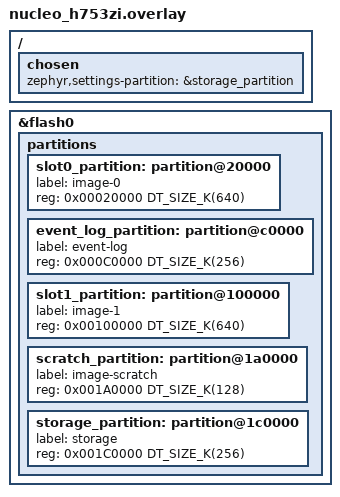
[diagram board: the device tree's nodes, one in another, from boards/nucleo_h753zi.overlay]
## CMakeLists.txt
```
cmake_minimum_required(VERSION 3.20.0)

# The following is optional and effectively ignored if a different board is chosen via a parameter.
# In general, it seems to be more appropriate to specify the board when invoking west or CMake
# directly, or, e.g., use `west config build.board nrf52840dk/nrf52840`.
#set(BOARD nucleo_h753zi)

# The following resolves the Zephyr location using the ZEPHYR_BASE environment variable.
# The `REQUIRED HINTS $ENV{ZEPHYR_BASE}` is optional in case you're not using `west zephyr-export`
# https://docs.zephyrproject.org/latest/develop/west/zephyr-cmds.html#installing-cmake-packages-west-zephyr-export
find_package(Zephyr REQUIRED HINTS $ENV{ZEPHYR_BASE})

project(
    example_1
    VERSION 0.1
    DESCRIPTION "A simple Zephyr application demonstrating a freestanding configuration."
    LANGUAGES C
)

target_include_directories(
        app
        PRIVATE
        include
)


# The target "app" is defined in Zephyr's CMake package and is the default target for Zephyr apps.
target_sources(
    app
    PRIVATE
    src/main.c
    src/blink_thread.c
    src/switch_thread.c
)
```

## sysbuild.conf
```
# Sysbuild configuration — co-builds MCUboot alongside the application.
# Used when building with: west build -b <board> --sysbuild
SB_CONFIG_BOOTLOADER_MCUBOOT=y
```

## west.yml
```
manifest:
  remotes:
    - name: zephyrproject-rtos
      url-base: https://github.com/zephyrproject-rtos

  projects:
    - name: zephyr
      remote: zephyrproject-rtos
      revision: main              # ← PINNED version! make sure your sdk version matches 
      import: true                   # ← This pulls in all Zephyr's module deps

  self:
    path: zephyr_freestanding
```

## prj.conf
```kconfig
# This project configuration is the default file expected by the build system.
# Unless a different file is specified using the `CONF_FILE` CMake variable, you'll need to
# provide this file even if it is empty.
#
# This template ships with optional features in src/ and include/ that are NOT
# compiled by default. To enable a feature you typically need three things:
#   1. Add the source file(s) to CMakeLists.txt
#   2. Uncomment the matching `# === <feature> ===` block below
#   3. (For event_log) ensure the board overlay defines event_log_partition
# See docs/feature_selection_guide.md for the per-feature recipe.

CONFIG_GPIO=y # Enable GPIO support, which is commonly used for controlling LEDs and reading button states.
CONFIG_PRINTK=y # Enable printk support for debugging output.

# === Logging ===
# CONFIG_LOG=y
# CONFIG_LOG_DEFAULT_LEVEL=3   # 0=off, 1=err, 2=warn, 3=info, 4=dbg

# === Persistent config (config_store: src/config_store.c) ==================
# Stores key-value settings on a dedicated flash partition (ZMS backend).
# Requires storage_partition in the board overlay (already defined in
# boards/nucleo_h753zi.overlay).
# CONFIG_FLASH=y
# CONFIG_FLASH_MAP=y
# CONFIG_FLASH_PAGE_LAYOUT=y
# CONFIG_ZMS=y
# CONFIG_SETTINGS=y
# CONFIG_SETTINGS_ZMS=y

# === Networking (W5500 + DHCP + sockets) ====================================
# Required by REST API, OTA, and any feature that talks over the network.
# CONFIG_NETWORKING=y
# CONFIG_NET_IPV4=y
# CONFIG_NET_TCP=y
# CONFIG_NET_UDP=y
# CONFIG_NET_SOCKETS=y
# CONFIG_NET_DHCPV4=y
# CONFIG_NET_L2_ETHERNET=y
# CONFIG_ETH_W5500=y
# CONFIG_SPI=y

# === HTTP server (REST API: src/rest_api.c) =================================
# Optional, requires Networking above.
# CONFIG_HTTP_SERVER=y
# CONFIG_HTTP_PARSER=y
# CONFIG_HTTP_PARSER_URL=y
# CONFIG_JSON_LIBRARY=y
# CONFIG_ZVFS=y
# CONFIG_ZVFS_EVENTFD=y
# CONFIG_ZVFS_EVENTFD_MAX=4   # bug_reports/016 — default of 1 is too small

# === MCUboot OTA + MCUmgr (UDP transport: src/ota.c) =======================
# Requires Networking above and a sysbuild build (`west build --sysbuild`).
# CONFIG_BOOTLOADER_MCUBOOT=y
# CONFIG_IMG_MANAGER=y
# CONFIG_STREAM_FLASH=y
# CONFIG_MCUMGR=y
# CONFIG_MCUMGR_TRANSPORT_UDP=y
# CONFIG_MCUMGR_GRP_IMG=y
# CONFIG_MCUMGR_GRP_OS=y

# === Event log (FCB ring: src/event_log.c) =================================
# Requires config_store, an event_log_partition in the board overlay
# (already defined in boards/nucleo_h753zi.overlay), and CONFIG_LOG above.
# CONFIG_FCB=y
# CONFIG_CRC=y

# === Time service (SNTP: src/time_service.c) ===============================
# Requires Networking and config_store above.
# CONFIG_SNTP=y
# CONFIG_POSIX_API=y
# CONFIG_POSIX_TIMERS=y
# CONFIG_DNS_RESOLVER=y
# CONFIG_DNS_SERVER_IP_ADDRESSES=y
# CONFIG_DNS_SERVER1="8.8.8.8"
```

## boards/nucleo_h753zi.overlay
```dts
/*
 * Application board overlay for nucleo_h753zi
 *
 * Replaces the default flash partition layout with an MCUboot-compatible
 * layout that includes:
 *   - a 256 KB storage partition for ZMS persistent settings, and
 *   - a 256 KB event-log partition (FCB ring buffer for event_log.c).
 *
 * Both sit outside the MCUboot swap area, so persistent state and event
 * history survive firmware updates.
 *
 * Flash layout (STM32H753 dual-bank, 2 MB total):
 *   0x08000000  boot_partition       128 KB  (MCUboot)
 *   0x08020000  slot0_partition      640 KB  (primary app image, bank 1)
 *   0x080C0000  event_log_partition  256 KB  (FCB ring, 2 x 128 KB sectors)
 *   0x08100000  slot1_partition      640 KB  (secondary image, bank 2 start)
 *   0x081A0000  scratch_partition    128 KB  (MCUboot swap scratch)
 *   0x081C0000  storage_partition    256 KB  (ZMS persistent settings)
 *                                    -------
 *                                    2048 KB total
 *
 * Slot1 deliberately starts at 0x100000 (bank 2) so MCUboot swaps stay
 * within a single bank's erase domain. The event-log partition fills the
 * tail of bank 1 between slot0 and the bank boundary.
 *
 * This overlay must match sysbuild/mcuboot/boards/nucleo_h753zi.overlay.
 */

/* Delete the base board's default partition nodes */
&flash0 {
    partitions {
        /delete-node/ partition@20000;  /* old slot0 */
        /delete-node/ partition@60000;  /* old slot1 */
        /delete-node/ partition@c0000;  /* old storage */

        /* Primary app image: 640 KB (5 x 128 KB sectors) */
        slot0_partition: partition@20000 {
            label = "image-0";
            reg = <0x00020000 DT_SIZE_K(640)>;
        };

        /* Event log FCB ring: 256 KB (2 x 128 KB sectors), tail of bank 1 */
        event_log_partition: partition@c0000 {
            label = "event-log";
            reg = <0x000C0000 DT_SIZE_K(256)>;
        };

        /* Secondary / upgrade image: 640 KB (bank 2 start) */
        slot1_partition: partition@100000 {
            label = "image-1";
            reg = <0x00100000 DT_SIZE_K(640)>;
        };

        /* MCUboot swap scratch: 128 KB */
        scratch_partition: partition@1a0000 {
            label = "image-scratch";
            reg = <0x001A0000 DT_SIZE_K(128)>;
        };

        /* ZMS persistent settings: 256 KB (outside MCUboot swap area) */
        storage_partition: partition@1c0000 {
            label = "storage";
            reg = <0x001C0000 DT_SIZE_K(256)>;
        };
    };
};

/* Point the settings subsystem at the storage partition */
/ {
    chosen {
        zephyr,settings-partition = &storage_partition;
    };
};
```

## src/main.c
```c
#include <zephyr/kernel.h>
#include "blink_thread.h"
#include "switch_thread.h"
#include "state_machines.h"

/*
 * ============================================================================
 * Optional module headers
 * ----------------------------------------------------------------------------
 * Uncomment the includes for the modules you enable in CMakeLists.txt and
 * prj.conf.  See docs/feature_selection_guide.md for the per-feature recipe.
 * ============================================================================
 */
/* #include "config_store.h" */
/* #include "w5500_net.h" */
/* #include "command_uart.h" */
/* #include "rest_api.h" */
/* #include "ota.h" */
/* #include "event_log.h" */
/* #include "time_service.h" */

/* mutex to protect access to shared state variables 
similar to python's threading.Lock, this ensures that only one thread can access the shared state variables at a time
*/
K_MUTEX_DEFINE(blink_led_mutex);  
K_MUTEX_DEFINE(blink_enabled_mutex);  

/* shared state variables */
volatile bool blink_enabled = true;
volatile struct gpio_dt_spec blinking_led;

int main(void)
{
    printk("Starting Zephyr Blinky with Threads Example\n");
    printk("blinking thread priority: %d, button thread priority: %d\n", BLINK_PRIORITY, BTN_PRIORITY);

    /* Initialize the blinking LED to led0 by default */
    blinking_led = led0;

    /* Create the blink thread */
    k_thread_create(&blink_thread_data, blink_stack, BLINK_STACK_SIZE,
                    blink_thread_entry, NULL, NULL, NULL,
                    BLINK_PRIORITY, 0, K_NO_WAIT);

    /* Create the button thread */
    k_thread_create(&btn_thread_data, btn_stack, BTN_STACK_SIZE,
                    btn_thread_entry, NULL, NULL, NULL,
                    BTN_PRIORITY, 0, K_NO_WAIT);

    /*
     * ========================================================================
     * Optional module thread spawns
     * ------------------------------------------------------------------------
     * Each block below corresponds to an optional feature module shipped in
     * src/ but NOT compiled by default.  Add the source file to
     * CMakeLists.txt, uncomment the matching block in prj.conf, and
     * uncomment the spawn here.  See docs/feature_selection_guide.md.
     *
     * Recommended spawn order (dependencies first):
     *   config_store -> w5500_net -> time_service -> event_log -> command_uart
     *   -> rest_api -> ota
     * ========================================================================
     */

    /* k_thread_create(&config_store_thread_data, config_store_stack,
     *                 CONFIG_STORE_STACK_SIZE, config_store_thread_entry,
     *                 NULL, NULL, NULL, CONFIG_STORE_PRIORITY, 0, K_NO_WAIT); */

    /* k_thread_create(&net_thread_data, net_stack, NET_STACK_SIZE,
     *                 net_thread_entry, NULL, NULL, NULL,
     *                 NET_PRIORITY, 0, K_NO_WAIT); */

    /* k_thread_create(&time_service_thread_data, time_service_stack,
     *                 TIME_SERVICE_STACK_SIZE, time_service_thread_entry,
     *                 NULL, NULL, NULL, TIME_SERVICE_PRIORITY, 0, K_NO_WAIT); */

    /* k_thread_create(&event_log_thread_data, event_log_stack,
     *                 EVENT_LOG_STACK_SIZE, event_log_thread_entry,
     *                 NULL, NULL, NULL, EVENT_LOG_PRIORITY, 0, K_NO_WAIT); */

    /* k_thread_create(&command_uart_thread_data, command_uart_stack,
     *                 COMMAND_UART_STACK_SIZE, command_uart_thread_entry,
     *                 NULL, NULL, NULL, COMMAND_UART_PRIORITY, 0, K_NO_WAIT); */

    /* k_thread_create(&rest_api_thread_data, rest_api_stack,
     *                 REST_API_STACK_SIZE, rest_api_thread_entry,
     *                 NULL, NULL, NULL, REST_API_PRIORITY, 0, K_NO_WAIT); */

    /* k_thread_create(&ota_thread_data, ota_stack, OTA_STACK_SIZE,
     *                 ota_thread_entry, NULL, NULL, NULL,
     *                 OTA_PRIORITY, 0, K_NO_WAIT); */

    printk("System started: 3 threads (main + button + blink)\n");

    while (1) {
        /* Main thread can perform other tasks or just sleep */
        k_sleep(K_FOREVER);
    }
    return 0;
}
```

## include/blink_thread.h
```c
#ifndef BLINK_THREAD_H
#define BLINK_THREAD_H

#define BLINK_STACK_SIZE 1024
#define BLINK_PRIORITY   3     /* Lower priority than button */

#include <stdbool.h>
#include <zephyr/kernel.h>
#include <zephyr/drivers/gpio.h>

#define LED0_NODE DT_ALIAS(led0)
#define LED1_NODE DT_ALIAS(led1)
extern const struct gpio_dt_spec led0;
extern const struct gpio_dt_spec led1;

extern struct k_thread blink_thread_data;
extern k_thread_stack_t blink_stack[];

/* entry point for the blink thread, this is where the blinking logic will be implemented */
void blink_thread_entry(void *p1, void *p2, void *p3); 
#endif /* BLINK_THREAD_H */
```

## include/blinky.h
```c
#ifndef BLINKY_H
#define BLINKY_H

#include <zephyr/drivers/gpio.h>

#define LED0_NODE DT_ALIAS(led0)
#define LED1_NODE DT_ALIAS(led1)
extern const struct gpio_dt_spec led0;
extern const struct gpio_dt_spec led1;
int blinky(void);
int led_init(void);


#endif /* BLINKY_H */
```

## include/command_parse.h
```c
#ifndef COMMAND_PARSE_H
#define COMMAND_PARSE_H

/**
 * @file command_parse.h
 * @brief Pure command-string parser for the UART interface.
 *
 * Converts a raw command string into a structured result (command ID
 * plus arguments) without performing any side effects.  This module
 * has no Zephyr dependencies and can be unit-tested on native_sim.
 */

#include <stddef.h>

/** Maximum length of a single argument extracted from a command. */
#define CMD_ARG_MAX_LEN 48

/** Recognised command identifiers. */
enum cmd_id {
    CMD_HELP,
    CMD_PING,
    CMD_IP_GET,
    CMD_IP_SET,
    CMD_IP_SET_DHCP,
    CMD_CONFIG_DUMP,
    CMD_CONFIG_FACTORY_RESET,
    CMD_EVENT_LOG,
    CMD_LOG_LEVEL_SET,
    CMD_LOG_DROP,
    CMD_TIME_GET,
    CMD_TIME_SET,
    CMD_TIME_SYNC,
    CMD_UNKNOWN,
};

/**
 * @brief Result of parsing a command string.
 *
 * `id` identifies the command.  For commands that accept positional
 * arguments (currently only `ip_set`) the first three space-separated
 * tokens after the keyword are stored in arg1 / arg2 / arg3.
 * Unused argument slots are zero-filled (empty strings).
 */
struct parsed_command {
    enum cmd_id id;
    char arg1[CMD_ARG_MAX_LEN];
    char arg2[CMD_ARG_MAX_LEN];
    char arg3[CMD_ARG_MAX_LEN];
};

/**
 * @brief Parse a null-terminated UART command string into a structured result.
 *
 * Leading whitespace is stripped.  The first token is matched against
 * known keywords (case-sensitive).  For `ip_set`, the three tokens
 * following the keyword are extracted into @p out->arg1 / arg2 / arg3.
 * If the input is empty after trimming, the command is reported as
 * CMD_UNKNOWN.  The function itself never fails on malformed input —
 * unrecognised strings yield CMD_UNKNOWN with return code 0.
 *
 * @param input Null-terminated command string received from UART.
 *              May be NULL (returns -1).
 * @param out   Output structure populated on return.
 *              May be NULL (returns -1).
 * @return 0 on success (including CMD_UNKNOWN), -1 only if a pointer is NULL.
 */
int parse_command(const char *input, struct parsed_command *out);

#endif /* COMMAND_PARSE_H */
```

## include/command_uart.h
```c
#ifndef COMMAND_UART_H
#define COMMAND_UART_H

/**
 * @file command_uart.h
 * @brief UART command interface module.
 *
 * Provides an interrupt-driven UART RX command interface
 * on the console UART. Supports a simple command dispatcher
 * that can be extended with application-specific commands.
 */

#include <zephyr/kernel.h>

/* ---------- Thread configuration ---------- */
#define UART_STACK_SIZE 1024
#define UART_PRIORITY   4

/* ---------- Thread resources (defined in uart.c) ---------- */
extern struct k_thread uart_thread_data;
extern k_thread_stack_t uart_stack[];

/* ---------- Module API ---------- */

/**
 * @brief UART module thread entry point.
 *
 * Initializes interrupt-driven UART RX, then loops waiting
 * for complete command lines and dispatching them.
 * Created by main() via k_thread_create().
 *
 * @param p1 Unused.
 * @param p2 Unused.
 * @param p3 Unused.
 */
void command_uart_thread_entry(void *p1, void *p2, void *p3);

#endif /* COMMAND_UART_H */
```

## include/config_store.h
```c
#ifndef CONFIG_STORE_H
#define CONFIG_STORE_H

/**
 * @file config_store.h
 * @brief Persistent configuration store using Zephyr's settings subsystem.
 *
 * Provides persistent key-value storage backed by ZMS flash. All configs
 * survive reboots and firmware updates (the storage partition is outside
 * the MCUboot slot0/slot1 swap area).
 *
 * Architecture:
 *   - Each config group (e.g. "heartbeat", "system") is a settings subtree.
 *   - The init thread calls settings_subsys_init -> settings_load -> dump.
 *   - Setters persist immediately via settings_save_one().
 *   - Thread-safe: a mutex protects all config variables.
 *
 * Adding a new config:
 *   1. Add a variable with a default in config_store.c
 *   2. Add a case in the h_set callback (for load from flash)
 *   3. Add an export line in h_export (for save-all)
 *   4. Add getter/setter functions
 *   5. Add a line to config_store_dump()
 */

#include <zephyr/kernel.h>
#include <stdbool.h>
#include <stdint.h>

/* ---------- Thread configuration ---------- */
#define CONFIG_STORE_STACK_SIZE  4096
#define CONFIG_STORE_PRIORITY    6

/* ---------- String length limits ---------- */
#define CONFIG_STORE_URL_MAX_LEN         256
#define CONFIG_STORE_NAME_MAX_LEN        64
#define CONFIG_STORE_NTP_SERVER_MAX_LEN  64
#define CONFIG_STORE_IP_ADDR_MAX_LEN    16  /* "255.255.255.255\0" */

/* ---------- Log verbosity (used by event_log) ---------- */

/**
 * @brief Log verbosity levels persisted under "event_log/logVerbosity".
 *
 * Maps to event_log severity filter:
 *   ERROR → drops WARN/NOTICE/INFO/DEBUG
 *   WARN  → drops NOTICE/INFO/DEBUG
 *   INFO  → drops only DEBUG
 *   DEBUG → logs everything
 */
enum mcu_log_verbosity {
    MCU_LOG_ERROR = 0,
    MCU_LOG_WARN  = 1,
    MCU_LOG_INFO  = 2,
    MCU_LOG_DEBUG = 3,
};

/* ---------- Thread resources (defined in config_store.c) ---------- */
extern struct k_thread config_store_thread_data;
extern k_thread_stack_t config_store_stack[];

void config_store_thread_entry(void *p1, void *p2, void *p3);
void config_store_dump(void);

/* ---------- heartbeat/ getters & setters ---------- */

bool config_store_get_heartbeat_enabled(void);
int config_store_set_heartbeat_enabled(bool enabled);
int config_store_get_heartbeat_url(char *buf, size_t buf_len);
int config_store_set_heartbeat_url(const char *url);
uint32_t config_store_get_heartbeat_interval(void);
int config_store_set_heartbeat_interval(uint32_t interval_s);

/* ---------- system/ getters & setters ---------- */

int config_store_get_system_name(char *buf, size_t buf_len);
int config_store_set_system_name(const char *name);

/* ---------- event_log/ getters & setters ---------- */

enum mcu_log_verbosity config_store_get_log_verbosity(void);
int config_store_set_log_verbosity(enum mcu_log_verbosity v);
uint32_t config_store_get_boot_count(void);
int config_store_set_boot_count(uint32_t count);

/* ---------- time_service/ getters & setters ---------- */

int config_store_get_ntp_server(char *buf, size_t buf_len);
int config_store_set_ntp_server(const char *server);
uint32_t config_store_get_ntp_sync_interval(void);
int config_store_set_ntp_sync_interval(uint32_t seconds);

/* ---------- network/ getters & setters ---------- */

int config_store_get_ip_address(char *buf, size_t buf_len);
int config_store_set_ip_address(const char *addr);
int config_store_get_ip_mask(char *buf, size_t buf_len);
int config_store_set_ip_mask(const char *mask);
int config_store_get_ip_gateway(char *buf, size_t buf_len);
int config_store_set_ip_gateway(const char *gw);

/* ---------- Factory reset ---------- */

int config_store_factory_reset(void);

#endif /* CONFIG_STORE_H */
```

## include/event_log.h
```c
#ifndef EVENT_LOG_H
#define EVENT_LOG_H

/**
 * @file event_log.h
 * @brief Flash-backed circular event log using Zephyr FCB.
 *
 * Provides a ring-buffer event log stored on a dedicated flash partition
 * ("event-log", 256 KB / 2 sectors).  Events are 76-byte fixed-size
 * records with a severity level modelled after Linux syslog (RFC 5424).
 *
 * The runtime filter level is driven by config_store's mcu_log_verbosity:
 *   MCU_LOG_ERROR → EVENT_SEV_ERR   (drops WARN/NOTICE/INFO/DEBUG)
 *   MCU_LOG_WARN  → EVENT_SEV_WARN  (drops NOTICE/INFO/DEBUG)
 *   MCU_LOG_INFO  → EVENT_SEV_INFO  (drops only DEBUG)
 *   MCU_LOG_DEBUG → EVENT_SEV_DEBUG (logs everything)
 *
 * Thread-safe — all public functions may be called from any context.
 *
 * To add a new event type:
 *   1. Add an entry to enum event_type (before EVENT_TYPE_COUNT).
 *   2. Add a string in event_type_to_str() in event_log.c.
 *   That's it — no registration required.
 */

#include <zephyr/kernel.h>
#include <stdint.h>
#include <stdbool.h>

/* ---------- Thread configuration ---------- */
#define EVENT_LOG_STACK_SIZE   2048
#define EVENT_LOG_PRIORITY     7
#define EVENT_LOG_MSG_MAX_LEN  64

/* ---------- Severity levels (RFC 5424 / Linux syslog) ---------- */

/**
 * @brief Event severity levels, modelled after Linux kernel log levels.
 *
 * Lower numeric value = higher severity.  The runtime filter drops
 * events whose severity value is strictly greater than the current level.
 *
 * @par Level table
 * | Value | Name   | Description                        |
 * |-------|--------|------------------------------------|
 * | 0     | EMERG  | System is unusable                 |
 * | 1     | ALERT  | Action must be taken immediately   |
 * | 2     | CRIT   | Critical conditions                |
 * | 3     | ERR    | Error conditions                   |
 * | 4     | WARN   | Warning conditions                 |
 * | 5     | NOTICE | Normal but significant             |
 * | 6     | INFO   | Informational messages             |
 * | 7     | DEBUG  | Debug-level messages               |
 */
enum event_severity {
    EVENT_SEV_EMERG  = 0,
    EVENT_SEV_ALERT  = 1,
    EVENT_SEV_CRIT   = 2,
    EVENT_SEV_ERR    = 3,
    EVENT_SEV_WARN   = 4,
    EVENT_SEV_NOTICE = 5,
    EVENT_SEV_INFO   = 6,
    EVENT_SEV_DEBUG  = 7,
};

/* ---------- Event types ---------- */

/**
 * @brief Categories of events recorded in the log.
 *
 * @par Type table
 * | Value | Name    | Typical use                        |
 * |-------|---------|------------------------------------|
 * | 0     | BOOT    | System boot / reboot               |
 * | 1     | NETWORK | DHCP, link up/down, IP changes     |
 * | 2     | OTA     | Image confirmed, upgrade started   |
 * | 3     | CONFIG  | Config store changes via REST API   |
 * | 4     | WEBHOOK | Keepalive / notification POST       |
 * | 5     | SYSTEM  | Module init, general system events  |
 * | 6     | USER    | User-triggered actions              |
 */
enum event_type {
    EVENT_TYPE_BOOT = 0,
    EVENT_TYPE_NETWORK,
    EVENT_TYPE_OTA,
    EVENT_TYPE_CONFIG,
    EVENT_TYPE_WEBHOOK,
    EVENT_TYPE_SYSTEM,
    EVENT_TYPE_USER,
    EVENT_TYPE_COUNT,
};

/* ---------- Event entry structure ---------- */

/**
 * @brief A single event log entry (80 bytes, packed).
 *
 * Stored directly in flash via FCB.
 *
 * Three independent timestamps tag each record:
 *   - `timestamp`  — uptime seconds (`k_uptime_get()/1000`). Resets on
 *                    every reboot, unique within a boot.
 *   - `wall_clock` — UNIX epoch seconds if the time service was
 *                    synced at write time, 0 otherwise. Monotonic
 *                    across reboots (once synced), but 0 for every
 *                    pre-sync entry.
 *   - `boot_id`    — persistent, monotonically-increasing boot
 *                    counter (`mcu/bootCount`). Stamps every record
 *                    with the boot session it was written in, so
 *                    cross-boot noise can be filtered out even when
 *                    `wall_clock` is 0 (see bug report #019).
 *
 * @par Memory layout
 * @code
 * Offset  Size  Field
 * 0       4     timestamp   (uint32_t — uptime seconds)
 * 4       4     wall_clock  (uint32_t — UNIX epoch seconds, 0 if unsynced)
 * 8       4     boot_id     (uint32_t — persistent boot counter)
 * 12      1     event_type  (uint8_t  — enum event_type)
 * 13      1     severity    (uint8_t  — enum event_severity)
 * 14      2     data_len    (uint16_t — actual message length)
 * 16      64    message     (char[]   — NUL-padded description)
 * Total: 80 bytes
 * @endcode
 */
typedef struct {
    uint32_t timestamp;
    uint32_t wall_clock;
    uint32_t boot_id;
    uint8_t  event_type;
    uint8_t  severity;
    uint16_t data_len;
    char     message[EVENT_LOG_MSG_MAX_LEN];
} __packed event_entry_t;

/* ---------- Walk callback ---------- */

/**
 * @brief Callback invoked for each event during event_log_read().
 *
 * @param entry     Pointer to the deserialized event entry.
 * @param user_data Opaque context pointer passed through from the caller.
 * @return true to continue walking, false to stop early.
 *
 * @par Example
 * @code
 * static bool print_event(const event_entry_t *e, void *ctx) {
 *     printk("[%u] %s\n", e->timestamp, e->message);
 *     return true;  // continue
 * }
 * int count = event_log_read(0, print_event, NULL);
 * @endcode
 */
typedef bool (*event_log_walk_cb)(const event_entry_t *entry, void *user_data);

/* ---------- Thread resources (defined in event_log.c) ---------- */
extern struct k_thread event_log_thread_data;
extern k_thread_stack_t event_log_stack[];

/* ---------- Public API ---------- */

/**
 * @brief Initialize the FCB event log subsystem.
 *
 * Opens the "event-log" flash partition, queries sector geometry,
 * and calls fcb_init().  Called automatically by the event_log thread,
 * but exposed for unit tests that don't spawn the thread.
 *
 * @return 0 on success, negative errno on failure.
 *
 * @par Example
 * @code
 * int rc = event_log_init();
 * // rc == 0  → FCB ready
 * // rc == -ENODEV → flash partition not found
 * @endcode
 */
int event_log_init(void);

/**
 * @brief Write an event to the log.
 *
 * If the event's severity value is greater than the current filter
 * level, the event is silently dropped (returns 0).  Messages longer
 * than EVENT_LOG_MSG_MAX_LEN (64) bytes are truncated.
 *
 * @param sev  Severity level (EVENT_SEV_EMERG … EVENT_SEV_DEBUG).
 * @param type Event category (EVENT_TYPE_BOOT … EVENT_TYPE_USER).
 * @param msg  Human-readable description (NUL-terminated, max 64 chars).
 * @return 0 on success (including filtered-out events), negative errno on
 *         flash write failure.
 *
 * @par Examples
 * | sev          | type              | msg                  | filter=INFO | Result     |
 * |--------------|-------------------|----------------------|-------------|------------|
 * | EVENT_SEV_INFO  | EVENT_TYPE_BOOT | "system boot"     | INFO        | Written    |
 * | EVENT_SEV_DEBUG | EVENT_TYPE_SYSTEM | "heartbeat tick" | INFO        | Dropped    |
 * | EVENT_SEV_ERR   | EVENT_TYPE_OTA  | "confirm failed"  | INFO        | Written    |
 *
 * @code
 * event_log_write(EVENT_SEV_INFO, EVENT_TYPE_BOOT, "system boot");
 * event_log_write(EVENT_SEV_WARN, EVENT_TYPE_NETWORK, "link down");
 * @endcode
 */
int event_log_write(enum event_severity sev, enum event_type type,
                    const char *msg);

/**
 * @brief Read events from the log, filtered by time and/or boot ID.
 *
 * Walks the FCB from oldest to newest and invokes @p cb for each
 * entry that passes all active filters.  If the callback returns
 * false, the walk stops early.
 *
 * The filter is asymmetric by design, because a `boot_id` is only
 * needed to disambiguate entries whose `wall_clock` is 0 (pre-sync
 * entries — where per-boot uptime aliases across reboots). Entries
 * written after SNTP sync already carry a monotonic, cross-reboot
 * `wall_clock`, so they are filtered purely by @p since_wall and
 * are emitted regardless of the boot they came from.
 *
 * Default (@p boot_id_strict == false):
 *   1. `entry.wall_clock != 0` — sync'd entries: pass if
 *      `since_wall == 0 || entry.wall_clock >= since_wall`,
 *      regardless of boot.
 *   2. `entry.wall_clock == 0` — pre-sync entries: emitted iff
 *      the entry's boot is "in scope" for the requested window:
 *        - the entry's boot_id equals @p boot_id (current boot's
 *          pre-sync is always shown), OR
 *        - the entry's boot_id is strictly greater than the
 *          smallest boot_id whose sync'd entries fell inside the
 *          wall window (`min_in_window`). Younger boots that
 *          started inside the window contribute their pre-sync
 *          banner / DHCP / SNTP-failed diagnostics; the boot
 *          that produced `min_in_window` itself is excluded
 *          because its pre-sync occurred *before* the window.
 *      Pre-sync entries also honour @p since_uptime when set.
 *      When the log contains no sync'd entry inside the window
 *      (no anchor), pre-sync emission collapses to "current boot
 *      only" (same as the iteration-4 rule).
 *
 * Strict (@p boot_id_strict == true):
 *   - Every entry (sync'd or not) must also have
 *     `entry.boot_id == boot_id`. Used by `event_log_boot <id>`
 *     to replay one specific boot's full log.
 *
 * @param since_wall       Wall-clock cutoff (UNIX epoch). 0 = no
 *                         wall filter.
 * @param since_uptime     Uptime cutoff (s) for pre-sync entries.
 *                         0 = no uptime filter.
 * @param boot_id          Boot ID (0 = no boot filter).
 * @param boot_id_strict   If true, @p boot_id applies to every
 *                         entry. If false, only to pre-sync entries.
 * @param cb               Callback invoked per matching entry.
 * @param user_data        Opaque pointer forwarded to @p cb.
 * @return Number of entries passed to the callback (>= 0), or
 *         negative errno on FCB read failure.
 *
 * @par Example
 * @code
 * uint32_t bid = event_log_get_boot_id();
 *
 * // "Last 300 s of wall time, plus current boot's pre-sync".
 * // Sync'd entries from previous boots that fall in the window
 * // are included (their wall clocks are authoritative).
 * event_log_read(now_wall - 300, 0, bid, false, cb, ud);
 *
 * // Full replay of boot 42 (strict).
 * event_log_read(0, 0, 42, true,  cb, ud);
 *
 * // Every entry ever written.
 * event_log_read(0, 0, 0, false, cb, ud);
 * @endcode
 */
int event_log_read(uint32_t since_wall, uint32_t since_uptime,
                   uint32_t boot_id, bool boot_id_strict,
                   event_log_walk_cb cb, void *user_data);

/**
 * @brief Return the boot ID stamped on every entry written during
 *        this boot session.
 *
 * The value is loaded and incremented once by `event_log_init()`
 * from the persistent counter `mcu/bootCount` in config_store.
 * It is stable for the lifetime of the firmware's run.
 *
 * @return Current boot ID (>= 1 after a successful init; 0 if
 *         `event_log_init()` has not yet completed).
 *
 * @par Example
 * @code
 * uint32_t id = event_log_get_boot_id();
 * printk("this boot has id %u\n", id);
 * @endcode
 */
uint32_t event_log_get_boot_id(void);

/**
 * @brief Erase all events from the log.
 *
 * Performs a full FCB clear (erases all sectors except scratch).
 *
 * @return 0 on success, negative errno on flash erase failure.
 *
 * @par Example
 * @code
 * event_log_clear();
 * int n = event_log_read(0, my_cb, NULL);
 * // n == 0
 * @endcode
 */
int event_log_clear(void);

/**
 * @brief Erase all events from the log (alias for event_log_clear).
 *
 * Provided for API clarity; identical to event_log_clear().
 */
static inline int event_log_drop_all(void) { return event_log_clear(); }

/**
 * @brief Set the runtime severity filter level.
 *
 * Events with severity > level are silently dropped by event_log_write().
 * Thread-safe (uses atomic store).
 *
 * @param level Maximum severity value to accept (EVENT_SEV_EMERG … EVENT_SEV_DEBUG).
 *
 * @par Example
 * @code
 * event_log_set_level(EVENT_SEV_WARN);
 * // Now only EMERG, ALERT, CRIT, ERR, WARN are logged
 *
 * event_log_set_level(EVENT_SEV_DEBUG);
 * // Everything is logged
 * @endcode
 */
void event_log_set_level(enum event_severity level);

/**
 * @brief Get the current runtime severity filter level.
 *
 * @return Current filter level (EVENT_SEV_EMERG … EVENT_SEV_DEBUG).
 *
 * @par Example
 * @code
 * enum event_severity lvl = event_log_get_level();
 * // lvl == EVENT_SEV_INFO (default after init with MCU_LOG_INFO)
 * @endcode
 */
enum event_severity event_log_get_level(void);

/**
 * @brief Convert a severity enum to a human-readable string.
 *
 * @param sev Severity value.
 * @return Static string pointer (e.g. "INFO", "ERR", "DEBUG").
 *
 * @par Examples
 * | Input            | Output   |
 * |------------------|----------|
 * | EVENT_SEV_EMERG  | "EMERG"  |
 * | EVENT_SEV_ERR    | "ERR"    |
 * | EVENT_SEV_INFO   | "INFO"   |
 * | EVENT_SEV_DEBUG  | "DEBUG"  |
 */
const char *severity_to_str(enum event_severity sev);

/**
 * @brief Convert an event type enum to a human-readable string.
 *
 * @param type Event type value.
 * @return Static string pointer (e.g. "BOOT", "NETWORK", "CONFIG").
 *
 * @par Examples
 * | Input               | Output    |
 * |---------------------|-----------|
 * | EVENT_TYPE_BOOT     | "BOOT"    |
 * | EVENT_TYPE_NETWORK  | "NETWORK" |
 * | EVENT_TYPE_CONFIG   | "CONFIG"  |
 */
const char *event_type_to_str(enum event_type type);

/**
 * @brief Event log thread entry point.
 *
 * Sequence:
 *   1. Call event_log_init() to mount the FCB partition.
 *   2. Read mcu_log_verbosity from config_store → set filter level.
 *   3. Log the current filter level to the serial debug output.
 *   4. Report ready to the OTA health check.
 *   5. Write a boot event: "system boot".
 *   6. Sleep forever — events are written from other threads.
 *
 * @param p1 Unused.
 * @param p2 Unused.
 * @param p3 Unused.
 */
void event_log_thread_entry(void *p1, void *p2, void *p3);

#endif /* EVENT_LOG_H */
```

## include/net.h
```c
#ifndef NET_H
#define NET_H

/**
 * @file net.h
 * @brief W5500 network module interface.
 *
 * Provides network initialization, static IP configuration,
 * and DHCPv4 management for the W5500 Ethernet controller.
 */

#include <zephyr/kernel.h>
#include <zephyr/net/net_ip.h>

/* ---------- Thread configuration ---------- */
#define NET_STACK_SIZE 2048
#define NET_PRIORITY   5

/* ---------- IPv4 configuration ---------- */
struct net_ipv4_config {
    struct in_addr addr;
    struct in_addr netmask;
    struct in_addr gw;
};

/* ---------- Thread resources (defined in net.c) ---------- */
extern struct k_thread net_thread_data;
extern k_thread_stack_t net_stack[];

/* ---------- Module API ---------- */

/**
 * @brief Net module thread entry point.
 *
 * Initializes the W5500 interface, registers DHCP callback,
 * and starts the DHCP client. Created by main() via k_thread_create().
 *
 * @param p1 Unused.
 * @param p2 Unused.
 * @param p3 Unused.
 */
void net_thread_entry(void *p1, void *p2, void *p3);

/**
 * Set the IPv4 address, netmask, and gateway on the default network interface.
 * Stops DHCP if running before applying static config.
 * Returns 0 on success, negative errno on failure.
 */
int net_set_ip(const struct net_ipv4_config *cfg);

/**
 * Start DHCPv4 on the default network interface.
 * Removes any existing static IPv4 addresses first.
 * Returns 0 on success, negative errno on failure.
 */
int net_set_dhcp(void);

/**
 * Get the current IPv4 configuration (address, netmask, gateway).
 * Works for both static and DHCP-assigned addresses.
 * Returns 0 on success, -ENODEV if no interface, -ENOENT if no address.
 */
int net_get_ip(struct net_ipv4_config *cfg);

#endif /* NET_H */
```

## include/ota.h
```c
#ifndef OTA_H
#define OTA_H

/**
 * @file ota.h
 * @brief OTA firmware update module interface.
 *
 * Provides MCUmgr-based OTA updates over UDP with a health-based
 * image confirmation system. Each application module reports its
 * readiness after successful initialization. The OTA thread waits
 * for all modules to report ready before confirming the running
 * image with MCUboot, preventing auto-revert of a known-good firmware.
 *
 * To add a new module to the health check:
 *   1. Add an entry to the ota_module enum (before OTA_MODULE_COUNT).
 *   2. Call ota_report_module_ready() from the module after init succeeds.
 *   That's it — the OTA thread automatically checks all registered modules.
 */

#include <zephyr/kernel.h>

/* ---------- Thread configuration ---------- */
#define OTA_STACK_SIZE         2048
#define OTA_PRIORITY           8
#define OTA_CONFIRM_TIMEOUT_S  30

/* ---------- Module health registry ---------- */

/**
 * @brief Enumeration of all application modules tracked by the OTA health system.
 *
 * Each module that must be healthy before an OTA image is confirmed
 * gets an entry here. OTA_MODULE_COUNT is always last and serves as
 * the total module count for the bitmask.
 *
 * Customize this enum for your application — add/remove entries as needed.
 * Max 32 modules (limited by atomic_t width).
 */
enum ota_module {
    OTA_MODULE_NET,          /**< Network — ready after interface up and DHCP started */
    OTA_MODULE_UART,         /**< Command UART — ready after IRQ enabled */
    OTA_MODULE_REST_API,     /**< REST API — ready after HTTP server started */
    OTA_MODULE_CONFIG_STORE, /**< Config store — ready after settings loaded */
    OTA_MODULE_EVENT_LOG,    /**< Event log — ready after FCB partition mounted */
    OTA_MODULE_TIME_SERVICE, /**< Time service — ready after init (sync may follow later) */
    OTA_MODULE_COUNT         /**< Sentinel — must be last. */
};

/* ---------- Firmware version (defined in ota.c) ---------- */

/**
 * @brief Get the firmware version string from MCUboot image header.
 *
 * Reads the running image's version field. Returns "unknown" if the
 * version cannot be read (e.g. when not running under MCUboot).
 *
 * @return Static string pointer (e.g. "0.1.0+0").
 */
const char *ota_get_fw_version(void);

/* ---------- Thread resources (defined in ota.c) ---------- */
extern struct k_thread ota_thread_data;
extern k_thread_stack_t ota_stack[];

/* ---------- Module API ---------- */

/**
 * @brief Report that a module has successfully initialized.
 *
 * Sets the corresponding bit in the health bitmask. Lock-free and
 * ISR-safe (uses atomic_or). Idempotent — calling twice is harmless.
 *
 * @param mod The module that is now ready (from enum ota_module).
 */
void ota_report_module_ready(enum ota_module mod);

/**
 * @brief OTA module thread entry point.
 *
 * Waits for all registered modules to report ready (up to
 * OTA_CONFIRM_TIMEOUT_S seconds), then confirms the running image
 * with MCUboot via boot_write_img_confirmed(). If not all modules
 * report in time, the image is left unconfirmed and MCUboot will
 * revert to the previous image on the next reset.
 *
 * When not running under MCUboot (e.g. direct flash via debugger),
 * the thread detects this and exits gracefully.
 *
 * @param p1 Unused.
 * @param p2 Unused.
 * @param p3 Unused.
 */
void ota_thread_entry(void *p1, void *p2, void *p3);

#endif /* OTA_H */
```

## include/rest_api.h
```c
#ifndef REST_API_H
#define REST_API_H

/**
 * @file rest_api.h
 * @brief HTTP REST API module interface.
 *
 * Provides an HTTP server on port 80 using Zephyr's built-in HTTP
 * server subsystem. Endpoints are registered declaratively using
 * HTTP_RESOURCE_DEFINE macros, making it easy to add new routes.
 *
 * The endpoint registry is a shared data source used by /index (HTML)
 * and /api/help (JSON) to auto-list every endpoint. Other modules
 * (e.g. rest_api_endpoints.c) add their HTTP_RESOURCE_DEFINE entries
 * and append to the registry so both pages stay in sync.
 */

#include <zephyr/kernel.h>
#include <zephyr/net/http/service.h>
#include <zephyr/sys/iterable_sections.h>

/* ---------- Thread configuration ---------- */
#define REST_API_STACK_SIZE 4096
#define REST_API_PRIORITY   7

/* ---------- Endpoint registry ---------- */

/**
 * @brief Describes a single registered API endpoint for /index and /api/help.
 *
 * Collected automatically by the linker via iterable sections.
 * Use ENDPOINT_ENTRY_DEFINE() to register an entry alongside its handler.
 */
struct endpoint_entry {
    const char *path;        /**< URL path, e.g. "/api/ping" */
    const char *method;      /**< HTTP method, e.g. "GET" */
    const char *description; /**< Human-readable description. */
};

/**
 * @brief Register an endpoint entry in the linker-collected registry.
 *
 * Place this macro next to the matching HTTP_RESOURCE_DEFINE so the
 * entry and handler stay together. /index and /api/help iterate
 * the section automatically.
 *
 * @param _name  Unique C identifier for this entry.
 * @param _path  URL path string.
 * @param _method HTTP method string ("GET", "POST", etc.).
 * @param _desc  Human-readable description string.
 */
#define ENDPOINT_ENTRY_DEFINE(_name, _path, _method, _desc) \
    const STRUCT_SECTION_ITERABLE(endpoint_entry, _name) = { \
        .path = _path, \
        .method = _method, \
        .description = _desc, \
    }

/**
 * @brief HTTP service instance shared by all endpoints.
 *
 * Defined in rest_api.c via HTTP_SERVICE_DEFINE. Other modules
 * reference this symbol in their HTTP_RESOURCE_DEFINE macros.
 */
extern const struct http_service_desc rest_api_svc;

/* ---------- Thread resources (defined in rest_api.c) ---------- */
extern struct k_thread rest_api_thread_data;
extern k_thread_stack_t rest_api_stack[];

/* ---------- Module API ---------- */

/**
 * @brief REST API module thread entry point.
 *
 * Starts the Zephyr HTTP server which listens on port 80.
 * All registered endpoints are served automatically by the
 * server's internal thread. This thread starts the server
 * and then sleeps, keeping the stack alive.
 *
 * @param p1 Unused.
 * @param p2 Unused.
 * @param p3 Unused.
 */
void rest_api_thread_entry(void *p1, void *p2, void *p3);

#endif /* REST_API_H */
```

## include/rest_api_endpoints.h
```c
#ifndef REST_API_ENDPOINTS_H
#define REST_API_ENDPOINTS_H

/**
 * @file rest_api_endpoints.h
 * @brief Example REST API endpoint declarations.
 *
 * All application-specific HTTP endpoints live here and in
 * rest_api_endpoints.c.  Each endpoint registers itself with
 * HTTP_RESOURCE_DEFINE against the shared rest_api_svc service
 * (declared in rest_api.h).
 *
 * Example endpoints implemented:
 *   POST /api/echo               - echo the JSON payload
 *   GET  /api/device/<name>/info - return the device name (wildcard path)
 */

#endif /* REST_API_ENDPOINTS_H */
```

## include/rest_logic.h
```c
#ifndef REST_LOGIC_H
#define REST_LOGIC_H

/**
 * @file rest_logic.h
 * @brief Pure request-parsing functions for the REST API.
 *
 * These functions extract and validate fields from JSON request
 * bodies without touching the HTTP layer. They depend only on
 * utils.h and can be unit-tested on native_sim.
 */

#include <stddef.h>

/**
 * @brief Parse a "set name" JSON request body.
 *
 * Extracts the value of the "name" key from the JSON body.
 *
 * @param body     JSON body string (not necessarily null-terminated).
 * @param body_len Length of the body in bytes.
 * @param name     Output buffer for the extracted name.
 * @param name_size Size of the output buffer.
 * @return 0 on success, -1 on missing / malformed field.
 */
int parse_set_name_request(const char *body, size_t body_len,
                           char *name, size_t name_size);

/**
 * @brief Parse a "set IP" JSON request body and validate the fields.
 *
 * Extracts "address", "mask", and "gateway" from the JSON body,
 * then validates them as a complete IPv4 configuration.
 *
 * @param body     JSON body string (not necessarily null-terminated).
 * @param body_len Length of the body in bytes.
 * @param addr     Output buffer for IP address.
 * @param mask     Output buffer for subnet mask.
 * @param gateway  Output buffer for gateway address.
 * @param buf_size Size of each output buffer.
 * @return 0 on success, -1 on missing field, -2 on validation failure.
 */
int parse_set_ip_request(const char *body, size_t body_len,
                         char *addr, char *mask, char *gateway,
                         size_t buf_size);

#endif /* REST_LOGIC_H */
```

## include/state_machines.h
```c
#ifndef STATE_MACHINES_H
#define STATE_MACHINES_H

#include <stdbool.h>
#include <zephyr/kernel.h>
#include <zephyr/drivers/gpio.h>

extern struct k_mutex blink_led_mutex; /* mutex to protect access to blinking LED state */
extern struct k_mutex blink_enabled_mutex; /* mutex to protect access to blink enabled state */
extern volatile bool blink_enabled;
extern volatile struct gpio_dt_spec blinking_led;

#endif /* STATE_MACHINES_H */
```
